# ATmega328PB device description
Architecture: AVR8; Family: megaAVR
Registers are 8-bit, access not given, no defined reset value unless marked. A register's access mark holds for its fields unless they carry their own. Offsets are from the block's base; [hi:lo] are bit positions; {n}, {i} and the like mark numbered series.

## TC4 (TC16 module)
Instances: TC4 0x00
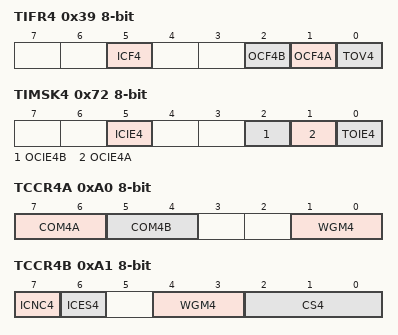
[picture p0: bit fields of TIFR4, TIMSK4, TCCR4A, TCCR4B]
0x39 TIFR4 — Timer/Counter4 Interrupt Flag register
  [5] ICF4 — Timer/Counter4 Input Capture Flag
  [2] OCF4B — Timer/Counter4 Output Compare B Match Flag
  [1] OCF4A — Timer/Counter4 Output Compare A Match Flag
  [0] TOV4 — Timer/Counter4 Overflow Flag
0x72 TIMSK4 — Timer/Counter4 Interrupt Mask Register
  [5] ICIE4 — Timer/Counter4 Input Capture Interrupt Enable
  [2] OCIE4B — Timer/Counter4 Output Compare B Match Interrupt Enable
  [1] OCIE4A — Timer/Counter4 Output Compare A Match Interrupt Enable
  [0] TOIE4 — Timer/Counter4 Overflow Interrupt Enable
0xA0 TCCR4A — Timer/Counter4 Control Register A
  [7:6] COM4A — Compare Output Mode 4A bits
  [5:4] COM4B — Compare Output Mode 4B bits
  [1:0] WGM4 — Waveform Generation Mode
0xA1 TCCR4B — Timer/Counter4 Control Register B
  [7] ICNC4 — Input Capture Noise Canceler
  [6] ICES4 — Input Capture Edge Select
  [4:3] WGM4 (bit 2 of the value upward) — Waveform Generation Mode
  [2:0] CS4 — Clock Select bits
    0=NO_CLOCK_SOURCE_STOPPED; 1=RUNNING_NO_PRESCALING; 2=RUNNING_CLK_8; 3=RUNNING_CLK_64; 4=RUNNING_CLK_256; 5=RUNNING_CLK_1024; 6=RUNNING_EXTCLK_TN_FALLING_EDGE; 7=RUNNING_EXTCLK_TN_RISING_EDGE
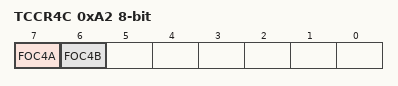
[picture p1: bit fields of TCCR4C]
0xA2 TCCR4C — Timer/Counter4 Control Register C
  [7] FOC4A — Force Output Compare for Channel A
  [6] FOC4B — Force Output Compare for Channel B
0xA4 TCNT4 16-bit — Timer/Counter4 Bytes
0xA6 ICR4 16-bit — Timer/Counter4 Input Capture Register Bytes
0xA8 OCR4A 16-bit — Timer/Counter4 Output Compare Register Bytes
0xAA OCR4B 16-bit — Timer/Counter4 Output Compare Register Bytes

## TC2 (TC8_ASYNC module) — Timer/Counter, 8-bit Async
Instances: TC2 0x00
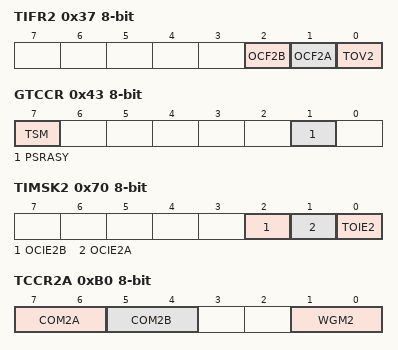
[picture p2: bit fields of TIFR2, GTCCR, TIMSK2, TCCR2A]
0x37 TIFR2 — Timer/Counter Interrupt Flag Register
  [2] OCF2B — Output Compare Flag 2B
  [1] OCF2A — Output Compare Flag 2A
  [0] TOV2 — Timer/Counter2 Overflow Flag
0x43 GTCCR — General Timer Counter Control register
  [7] TSM — Timer/Counter Synchronization Mode
  [1] PSRASY — Prescaler Reset Timer/Counter2
0x70 TIMSK2 — Timer/Counter Interrupt Mask register
  [2] OCIE2B — Timer/Counter2 Output Compare Match B Interrupt Enable
  [1] OCIE2A — Timer/Counter2 Output Compare Match A Interrupt Enable
  [0] TOIE2 — Timer/Counter2 Overflow Interrupt Enable
0xB0 TCCR2A — Timer/Counter2 Control Register A
  [7:6] COM2A — Compare Output Mode bits
  [5:4] COM2B — Compare Output Mode bits
  [1:0] WGM2 — Waveform Generation Mode
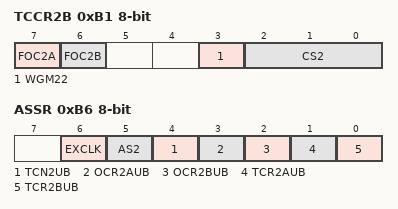
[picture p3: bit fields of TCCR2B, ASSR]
0xB1 TCCR2B — Timer/Counter2 Control Register B
  [7] FOC2A — Force Output Compare A
  [6] FOC2B — Force Output Compare B
  [3] WGM22 — Waveform Generation Mode
  [2:0] CS2 — Clock Select bits
    0=NO_CLOCK_SOURCE_STOPPED; 1=RUNNING_NO_PRESCALING; 2=RUNNING_CLK_8; 3=RUNNING_CLK_32; 4=RUNNING_CLK_64; 5=RUNNING_CLK_128; 6=RUNNING_CLK_256; 7=RUNNING_CLK_1024
0xB2 TCNT2 — Timer/Counter2
0xB3 OCR2A — Timer/Counter2 Output Compare Register A
0xB4 OCR2B — Timer/Counter2 Output Compare Register B
0xB6 ASSR — Asynchronous Status Register
  [6] EXCLK — Enable External Clock Input
  [5] AS2 — Asynchronous Timer/Counter2
  [4] TCN2UB — Timer/Counter2 Update Busy
  [3] OCR2AUB — Output Compare Register2 Update Busy
  [2] OCR2BUB — Output Compare Register 2 Update Busy
  [1] TCR2AUB — Timer/Counter Control Register2 Update Busy
  [0] TCR2BUB — Timer/Counter Control Register2 Update Busy

## ADC — Analog-to-Digital Converter
Instances: ADC 0x00
0x78 ADC 16-bit — ADC Data Register Bytes
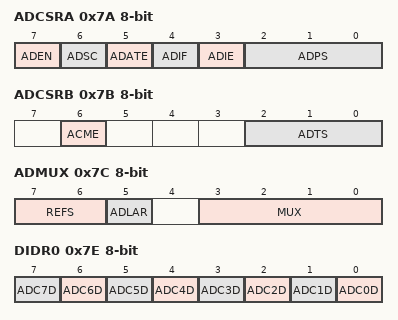
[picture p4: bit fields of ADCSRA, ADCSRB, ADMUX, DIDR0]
0x7A ADCSRA — The ADC Control and Status register A
  [7] ADEN — ADC Enable
  [6] ADSC — ADC Start Conversion
  [5] ADATE — ADC Auto Trigger Enable
  [4] ADIF — ADC Interrupt Flag
  [3] ADIE — ADC Interrupt Enable
  [2:0] ADPS — ADC Prescaler Select Bits
    0=2; 1=2; 2=4; 3=8; 4=16; 5=32; 6=64; 7=128
0x7B ADCSRB — The ADC Control and Status register B
  [6] ACME — Analog Comparator Multiplexer Enable
  [2:0] ADTS — ADC Auto Trigger Source bits
    0=FREE_RUNNING_MODE; 1=ANALOG_COMPARATOR; 2=EXTERNAL_INTERRUPT_REQUEST_0; 3=TIMER_COUNTER0_COMPARE_MATCH_A; 4=TIMER_COUNTER0_OVERFLOW; 5=TIMER_COUNTER1_COMPARE_MATCH_B; 6=TIMER_COUNTER1_OVERFLOW; 7=TIMER_COUNTER1_CAPTURE_EVENT
0x7C ADMUX — The ADC multiplexer Selection Register
  [7:6] REFS — Reference Selection Bits
    0=AREF_INTERNAL_VREF_TURNED_OFF; 1=AVCC_WITH_EXTERNAL_CAPACITOR_AT_AREF_PIN; 3=INTERNAL_1_1V_VOLTAGE_REFERENCE_WITH_EXTERNAL_CAPACITOR_AT_AREF_PIN
  [5] ADLAR — Left Adjust Result
  [3:0] MUX — Analog Channel Selection Bits
    {v}=ADC{v} (ADC Single Ended Input pin {v}) (v=0..7); 8=TEMPSENS (Temperature sensor); 14=ADC_VBG (Internal Reference (VBG)); 15=ADC_GND (0V (GND))
0x7E DIDR0 — Digital Input Disable Register
  [n] ADC{n}D (n=0..7) — ADC Digital Input Disable
